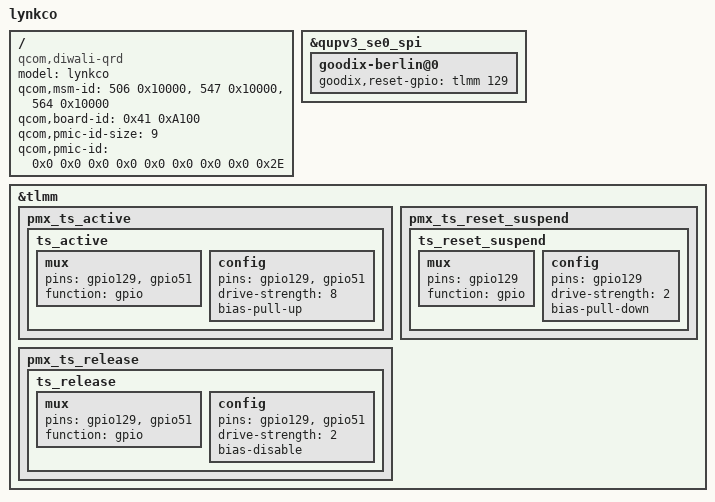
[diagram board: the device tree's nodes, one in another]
/* Copyright (c) 2022, The Linux Foundation. All rights reserved.
 *
 * This program is free software; you can redistribute it and/or modify
 * it under the terms of the GNU General Public License version 2 and
 * only version 2 as published by the Free Software Foundation.
 *
 * This program is distributed in the hope that it will be useful,
 * but WITHOUT ANY WARRANTY; without even the implied warranty of
 * MERCHANTABILITY or FITNESS FOR A PARTICULAR PURPOSE.  See the
 * GNU General Public License for more details.
 */

/dts-v1/;
/plugin/;

#include "diwali-lynkco-common-overlay.dtsi"

/ {
	model = "lynkco";
	compatible = "qcom,diwali-qrd", "qcom,diwali", "qcom,qrd", "moto,lynkco";
	qcom,msm-id = <506 0x10000>, <547 0x10000>, <564 0x10000>;
	qcom,board-id = <0x41 0xA100>;
	qcom,pmic-id-size = <9>;
	qcom,pmic-id = <0x0 0x0 0x0 0x0 0x0 0x0 0x0 0x0 0x2E>;
};

&qupv3_se0_spi {
	goodix-berlin@0 {
		goodix,reset-gpio = <&tlmm 129 0x0>;
	};
};

/* touchscreen pins */
&tlmm {
	pmx_ts_active {
		ts_active: ts_active {
			mux {
				pins = "gpio129", "gpio51";
				function = "gpio";
			};

			config {
				pins = "gpio129", "gpio51";
				drive-strength = <8>;
				bias-pull-up;
			};
		};
	};

	pmx_ts_reset_suspend {
		ts_reset_suspend: ts_reset_suspend {
			mux {
				pins = "gpio129";
				function = "gpio";
			};

			config {
				pins = "gpio129";
				drive-strength = <2>;
				bias-pull-down;
			};
		};
	};

	pmx_ts_release {
		ts_release: ts_release {
			mux {
				pins = "gpio129", "gpio51";
				function = "gpio";
			};

			config {
				pins = "gpio129", "gpio51";
				drive-strength = <2>;
				bias-disable;
			};
		};
	};
};
